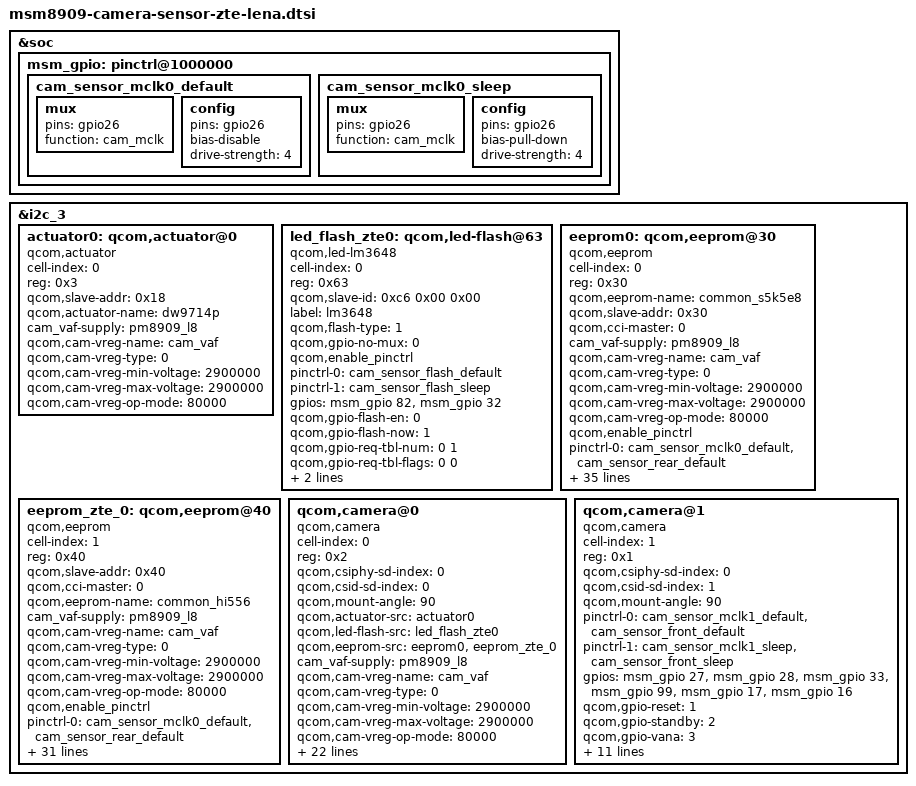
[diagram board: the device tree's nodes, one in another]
/*
 * Copyright (c) 2014-2015, The Linux Foundation. All rights reserved.
 *
 * This program is free software; you can redistribute it and/or modify
 * it under the terms of the GNU General Public License version 2 and
 * only version 2 as published by the Free Software Foundation.
 *
 * This program is distributed in the hope that it will be useful,
 * but WITHOUT ANY WARRANTY; without even the implied warranty of
 * MERCHANTABILITY or FITNESS FOR A PARTICULAR PURPOSE.  See the
 * GNU General Public License for more details.
 */

&soc {
    msm_gpio: pinctrl@1000000{
			cam_sensor_mclk0_default: cam_sensor_mclk0_default {
				/* MCLK0 */
				mux {
					/* CLK, DATA */
					pins = "gpio26";
					function = "cam_mclk";
				};

				config {
					pins = "gpio26";
					bias-disable; /* No PULL */
					drive-strength = <4>; /* 4 MA */
				};
			};

			cam_sensor_mclk0_sleep: cam_sensor_mclk0_sleep {
				/* MCLK0 */
				mux {
					/* CLK, DATA */
					pins = "gpio26";
					function = "cam_mclk";
				};

				config {
					pins = "gpio26";
					bias-pull-down; /* PULL DOWN */
					drive-strength = <4>; /* 4 MA */
				};
			};
		};
};

&i2c_3 {
 /* add zte sensor dtsi for actuator bu64291*/
	actuator0: qcom,actuator@0 {
		cell-index = <0>;
		reg = <0x3>;
		qcom,slave-addr = <0x18>;
		compatible = "qcom,actuator";
		qcom,actuator-name = "dw9714p";
		/*qcom,cci-master = <0>;*/
		cam_vaf-supply = <&pm8909_l8>;
		qcom,cam-vreg-name = "cam_vaf";
		qcom,cam-vreg-type = <0>;
		qcom,cam-vreg-min-voltage = <2900000>;
		qcom,cam-vreg-max-voltage = <2900000>;
		qcom,cam-vreg-op-mode = <80000>;
		status = "ok";
	};

    /* add zte sensor dtsi for led-flash*/
	led_flash_zte0: qcom,led-flash@63 {
		cell-index = <0>;
		reg = <0x63>;
		qcom,slave-id = <0xc6 0x00 0x00>;
		compatible = "qcom,led-lm3648";
		label = "lm3648";
		qcom,flash-type = <1>;
		qcom,gpio-no-mux = <0>;
		qcom,enable_pinctrl;
		pinctrl-names = "cam_flash_default", "cam_flash_suspend";
		pinctrl-0 = <&cam_sensor_flash_default>;
		pinctrl-1 = <&cam_sensor_flash_sleep>;
		gpios = <&msm_gpio 82 0>,
			<&msm_gpio 32 0>;
		qcom,gpio-flash-en = <0>;
		qcom,gpio-flash-now = <1>;
		qcom,gpio-req-tbl-num = <0 1>;
		qcom,gpio-req-tbl-flags = <0 0>;
		qcom,gpio-req-tbl-label = "FLASH_EN",
			"FLASH_NOW";
		qcom,cci-master = <0>;
		status = "ok";
	};

	eeprom0: qcom,eeprom@30{
		cell-index = <0>;
		reg = <0x30>;
		qcom,eeprom-name = "common_s5k5e8";
		compatible = "qcom,eeprom";
		qcom,slave-addr = <0x30>;
		qcom,cci-master = <0>;
		cam_vaf-supply = <&pm8909_l8>;
		qcom,cam-vreg-name = "cam_vaf";
		qcom,cam-vreg-type = <0>;
		qcom,cam-vreg-min-voltage = <2900000>;
		qcom,cam-vreg-max-voltage = <2900000>;
		qcom,cam-vreg-op-mode = <80000>;
		qcom,enable_pinctrl;
		pinctrl-names = "cam_default", "cam_suspend";
		pinctrl-0 = <&cam_sensor_mclk0_default
				&cam_sensor_rear_default>;
		pinctrl-1 = <&cam_sensor_mclk0_sleep
				&cam_sensor_rear_sleep>;
		gpios = <&msm_gpio 26 0>,
			<&msm_gpio 35 0>,
			<&msm_gpio 34 0>,
			<&msm_gpio 16 0>,
			<&msm_gpio 99 0>,
			<&msm_gpio 17 0>;
		qcom,gpio-reset = <1>;
		qcom,gpio-standby = <2>;
		qcom,gpio-vdig = <3>;
		qcom,gpio-vana = <4>;
		qcom,gpio-vio = <5>;
		qcom,gpio-req-tbl-num = <0 1 2 3 4 5>;
		qcom,gpio-req-tbl-flags = <1 0 0 0 0 0>;
		qcom,gpio-req-tbl-label = "CAMIF_MCLK",
			"CAM_RESET",
			"CAM_STANDBY",
			"CAM_VDIG",
			"CAM_VANA",
			"CAM_VIO";
		qcom,cam-power-seq-type = "sensor_gpio",
			"sensor_gpio",
			"sensor_gpio",
			"sensor_gpio",
			"sensor_gpio",
			"sensor_vreg",
			"sensor_clk",
			"sensor_gpio",
			"sensor_gpio",
			"sensor_i2c_mux";
		qcom,cam-power-seq-val = "sensor_gpio_standby",
			"sensor_gpio_reset",
			"sensor_gpio_vdig",
			"sensor_gpio_vana",
			"sensor_gpio_vio",
			"cam_vaf",
			"sensor_cam_mclk",
			"sensor_gpio_standby",
			"sensor_gpio_reset",
			"none";
		qcom,cam-power-seq-cfg-val = < 0 0 1 1 1 1 24000000 1 1 0>;
		qcom,cam-power-seq-delay =   < 1 1 3 3 3 3 10 1 1 0>;
		zte,num-blocks = <5>;
		zte,mem0    = <1 0x0a33 2 0x0 1 0>;   //lsc  FLAG
		zte,mem1    = <19   0x0a05 2 0x0 1 0>;	//AWB group1  no flag1
		zte,mem2    = <19   0x0a1a 2 0x0 1 0>;  //AWB group2    no flag2
		zte,mem3    = <4   0x0a05 2 0x0 1 0>;  //AF group1    no flag1 no checksum
		zte,mem4    = <4   0x0a0f 2 0x0 1 0>;    //AF group2  no flag2 no checksum
		clocks = <&clock_gcc clk_mclk0_clk_src>,
				<&clock_gcc clk_gcc_camss_mclk0_clk>;
		clock-names = "cam_src_clk", "cam_clk";
		qcom,clock-rates = <24000000 0>;
		status = "ok";
	};

	eeprom_zte_0: qcom,eeprom@40{
		compatible = "qcom,eeprom";
		cell-index = <1>;
		reg = <0x40>;
		qcom,slave-addr = <0x40>;
		qcom,cci-master = <0>;
		qcom,eeprom-name = "common_hi556";
		cam_vaf-supply = <&pm8909_l8>;
		qcom,cam-vreg-name = "cam_vaf";
		qcom,cam-vreg-type = <0>;
		qcom,cam-vreg-min-voltage = <2900000>;
		qcom,cam-vreg-max-voltage = <2900000>;
		qcom,cam-vreg-op-mode = <80000>;
		qcom,enable_pinctrl;
		pinctrl-names = "cam_default", "cam_suspend";
		pinctrl-0 = <&cam_sensor_mclk0_default
				&cam_sensor_rear_default>;
		pinctrl-1 = <&cam_sensor_mclk0_sleep
				&cam_sensor_rear_sleep>;
		gpios = <&msm_gpio 26 0>,
			<&msm_gpio 35 0>,
			<&msm_gpio 34 0>,
			<&msm_gpio 16 0>,
			<&msm_gpio 99 0>,
			<&msm_gpio 17 0>;
		qcom,gpio-reset = <1>;
		qcom,gpio-standby = <2>;
		qcom,gpio-vdig = <3>;
		qcom,gpio-vana = <4>;
		qcom,gpio-vio = <5>;
		qcom,gpio-req-tbl-num = <0 1 2 3 4 5>;
		qcom,gpio-req-tbl-flags = <1 0 0 0 0 0>;
		qcom,gpio-req-tbl-label = "CAMIF_MCLK",
			"CAM_RESET",
			"CAM_STANDBY",
			"CAM_VDIG",
			"CAM_VANA",
			"CAM_VIO";
		qcom,cam-power-seq-type = "sensor_gpio",
			"sensor_gpio",
			"sensor_gpio",
			"sensor_gpio",
			"sensor_gpio",
			"sensor_vreg",
			"sensor_clk",
			"sensor_gpio",
			"sensor_gpio",
			"sensor_i2c_mux";
		qcom,cam-power-seq-val = "sensor_gpio_standby",
			"sensor_gpio_reset",
			"sensor_gpio_vdig",
			"sensor_gpio_vana",
			"sensor_gpio_vio",
			"cam_vaf",
			"sensor_cam_mclk",
			"sensor_gpio_standby",
			"sensor_gpio_reset",
			"none";
		qcom,cam-power-seq-cfg-val = < 0 0 1 1 1 1 24000000 1 1 0>;
		qcom,cam-power-seq-delay =   < 1 1 3 3 3 3 10 1 1 0>;
		zte,num-blocks = <1>;
		zte,mem0 = <2351 0x0a3e 2 0x0 1 0>; //lsc  FLAG
		clocks = <&clock_gcc clk_mclk0_clk_src>,
				<&clock_gcc clk_gcc_camss_mclk0_clk>;
		clock-names = "cam_src_clk", "cam_clk";
		qcom,clock-rates = <24000000 0>;
		status = "ok";
	};

	qcom,camera@0 {
		cell-index = <0>;
		compatible = "qcom,camera";
		reg = <0x2>;
		qcom,csiphy-sd-index = <0>;
		qcom,csid-sd-index = <0>;
		qcom,mount-angle = <90>;
		qcom,actuator-src = <&actuator0>;
		qcom,led-flash-src = <&led_flash_zte0>;
		qcom,eeprom-src = <&eeprom0 &eeprom_zte_0>;
		cam_vaf-supply = <&pm8909_l8>;
		qcom,cam-vreg-name = "cam_vaf";
		qcom,cam-vreg-type = <0>;
		qcom,cam-vreg-min-voltage = <2900000>;
		qcom,cam-vreg-max-voltage = <2900000>;
		qcom,cam-vreg-op-mode = <80000>;
		pinctrl-names = "cam_default", "cam_suspend";
		pinctrl-0 = <&cam_sensor_mclk0_default
				&cam_sensor_rear_default>;
		pinctrl-1 = <&cam_sensor_mclk0_sleep
				&cam_sensor_rear_sleep>;
		gpios = <&msm_gpio 26 0>,
			<&msm_gpio 35 0>,
			<&msm_gpio 34 0>,
			<&msm_gpio 16 0>,
			<&msm_gpio 99 0>,
			<&msm_gpio 17 0>;
		qcom,gpio-reset = <1>;
		qcom,gpio-standby = <2>;
		qcom,gpio-vdig = <3>;
		qcom,gpio-vana = <4>;
		qcom,gpio-vio = <5>;
		qcom,gpio-req-tbl-num = <0 1 2 3 4 5>;
		qcom,gpio-req-tbl-flags = <1 0 0 0 0 0>;
		qcom,gpio-req-tbl-label = "CAMIF_MCLK",
			"CAM_RESET",
			"CAM_STANDBY",
			"CAM_VDIG",
			"CAM_VANA",
			"CAM_VIO";
		qcom,sensor-position = <0>;
		qcom,sensor-mode = <0>;
		qcom,cci-master = <0>;
		status = "ok";
		clocks = <&clock_gcc clk_mclk0_clk_src>,
				<&clock_gcc clk_gcc_camss_mclk0_clk>;
		clock-names = "cam_src_clk", "cam_clk";
		qcom,clock-rates = <24000000 0>;
	};

	qcom,camera@1 {
		cell-index = <1>;
		compatible = "qcom,camera";
		reg = <0x1>;
		qcom,csiphy-sd-index = <0>;
		qcom,csid-sd-index = <1>;
		qcom,mount-angle = <90>;
		pinctrl-names = "cam_default", "cam_suspend";
		pinctrl-0 = <&cam_sensor_mclk1_default &cam_sensor_front_default>;
		pinctrl-1 = <&cam_sensor_mclk1_sleep &cam_sensor_front_sleep>;
		gpios = <&msm_gpio 27 0>,
			<&msm_gpio 28 0>,
			<&msm_gpio 33 0>,
			<&msm_gpio 99 0>,
			<&msm_gpio 17 0>,
			<&msm_gpio 16 0>;
		qcom,gpio-reset = <1>;
		qcom,gpio-standby = <2>;
		qcom,gpio-vana = <3>;
		qcom,gpio-vio = <4>;
		qcom,gpio-custom1 = <5>;
		qcom,gpio-req-tbl-num = <0 1 2 3 4 5>;
		qcom,gpio-req-tbl-flags = <1 0 0 0 0 0>;
		qcom,gpio-req-tbl-label = "CAMIF_MCLK",
			"CAM_RESET",
			"CAM_STANDBY",
			"CAM_VANA",
			"CAM_VIO",
			"CAM_V_CUSTOM1";
		qcom,cci-master = <0>;
		status = "ok";
		clocks = <&clock_gcc clk_mclk1_clk_src>,
				<&clock_gcc clk_gcc_camss_mclk1_clk>;
		clock-names = "cam_src_clk", "cam_clk";
		qcom,clock-rates = <24000000 0>;
	};
};
